VERSION ""

NS_ :

BS_:

BU_: EON PED IBST EPAS GAS_ACTUATOR BRAKE_ACTUATOR STEER_ACTUATOR XXX

CM_ "Ocelot retrofit hardware CAN definitions";
CM_ "Source: github.com/RetroPilot/opendbc branch c2";
CM_ "Used by PriusPilot for aftermarket actuator control on Prius Gen 2 (NHW20)";

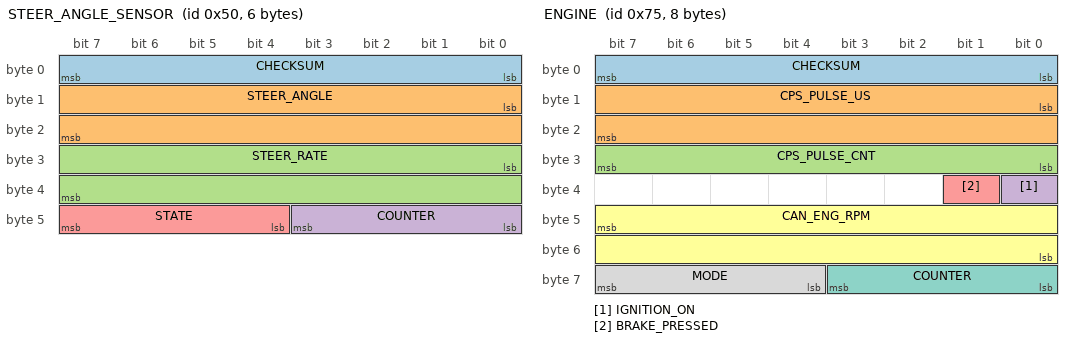
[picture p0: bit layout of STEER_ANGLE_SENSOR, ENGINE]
BO_ 80 STEER_ANGLE_SENSOR: 6 XXX
 SG_ CHECKSUM : 0|8@1+ (1,0) [0|255] "" XXX
 SG_ STEER_ANGLE : 8|16@1- (0.1,0) [0|65535] "" XXX
 SG_ STEER_RATE : 24|16@1+ (1,0) [0|65535] "" XXX
 SG_ COUNTER : 40|4@1+ (1,0) [0|15] "" XXX
 SG_ STATE : 44|4@1+ (1,0) [0|15] "" XXX

BO_ 117 ENGINE: 8 XXX
 SG_ CHECKSUM : 0|8@1+ (1,0) [0|255] "" XXX
 SG_ CPS_PULSE_US : 8|16@1+ (1,0) [0|65535] "" XXX
 SG_ CPS_PULSE_CNT : 24|8@1+ (1,0) [0|255] "" XXX
 SG_ IGNITION_ON : 32|1@0+ (1,0) [0|1] "" XXX
 SG_ BRAKE_PRESSED : 33|1@0+ (1,0) [0|1] "" XXX
 SG_ CAN_ENG_RPM : 47|16@0+ (1,0) [0|65535] "" XXX
 SG_ COUNTER : 56|4@1+ (1,0) [0|7] "" XXX
 SG_ MODE : 60|4@1+ (1,0) [0|15] "" XXX

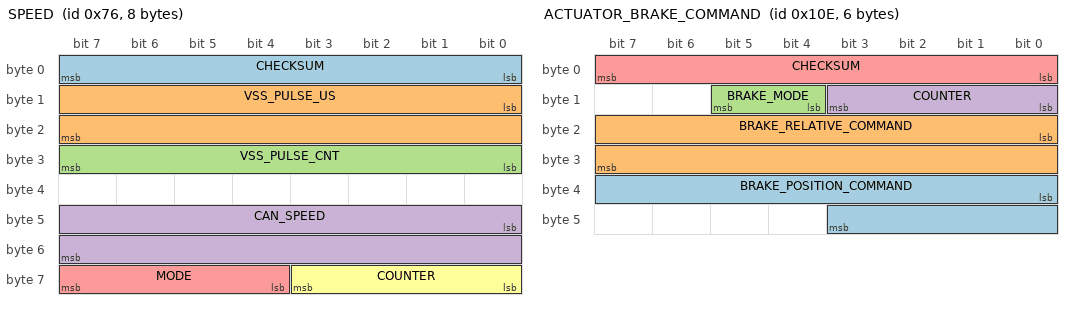
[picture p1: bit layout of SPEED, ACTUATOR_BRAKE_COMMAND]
BO_ 118 SPEED: 8 XXX
 SG_ CHECKSUM : 0|8@1+ (1,0) [0|255] "" XXX
 SG_ VSS_PULSE_US : 8|16@1+ (1,0) [0|65535] "" XXX
 SG_ VSS_PULSE_CNT : 24|8@1+ (1,0) [0|255] "" XXX
 SG_ CAN_SPEED : 40|16@1+ (1,0) [0|16777215] "" XXX
 SG_ MODE : 60|4@1+ (1,0) [0|15] "" XXX
 SG_ COUNTER : 56|4@1+ (1,0) [0|15] "" XXX

BO_ 256 CRUISE: 8 XXX
 SG_ CHECKSUM : 0|8@1+ (1,0) [0|255] "" XXX
 SG_ CANCEL : 16|1@1+ (1,0) [0|1] "" XXX
 SG_ SET_DOWN : 17|1@1+ (1,0) [0|1] "" XXX
 SG_ RES_UP : 18|1@1+ (1,0) [0|1] "" XXX
 SG_ ON_OFF : 19|1@1+ (1,0) [0|1] "" XXX
 SG_ ADC_1 : 31|16@1+ (1,0) [0|65535] "" XXX
 SG_ ADC_2 : 47|16@1+ (1,0) [0|65535] "" XXX
 SG_ COUNTER : 56|4@1+ (1,0) [0|15] "" XXX
 SG_ MODE : 60|4@1+ (1,0) [0|15] "" XXX

BO_ 270 ACTUATOR_BRAKE_COMMAND: 6 EON
 SG_ BRAKE_POSITION_COMMAND : 32|12@1+ (0.015625,-5) [-5|47] "mm" BRAKE_ACTUATOR
 SG_ BRAKE_RELATIVE_COMMAND : 16|16@1+ (0.0078125,-252) [-252|252] "" BRAKE_ACTUATOR
 SG_ BRAKE_MODE : 12|2@1+ (1,0) [0|3] "" BRAKE_ACTUATOR
 SG_ COUNTER : 8|4@1+ (1,0) [0|15] "" BRAKE_ACTUATOR
 SG_ CHECKSUM : 0|8@1+ (1,0) [0|255] "" BRAKE_ACTUATOR

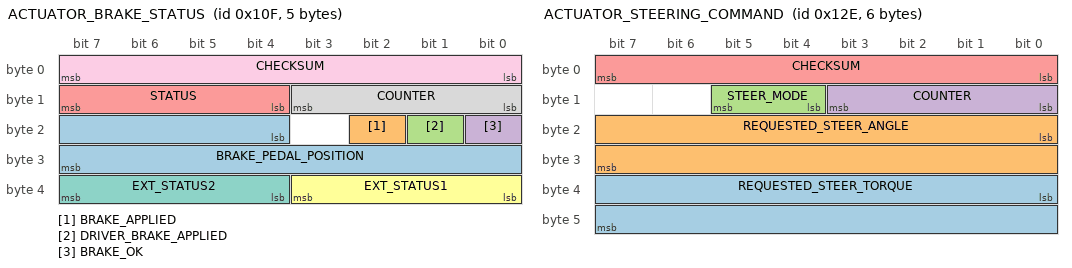
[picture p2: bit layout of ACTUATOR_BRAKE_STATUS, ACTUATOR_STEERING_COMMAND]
BO_ 271 ACTUATOR_BRAKE_STATUS: 5 BRAKE_ACTUATOR
 SG_ BRAKE_PEDAL_POSITION : 20|12@1+ (0.015625,-5) [-5|47] "mm" EON
 SG_ BRAKE_APPLIED : 18|1@1+ (1,0) [0|1] "" EON
 SG_ DRIVER_BRAKE_APPLIED : 17|1@1+ (1,0) [0|1] "" EON
 SG_ BRAKE_OK : 16|1@1+ (1,0) [0|1] "" EON
 SG_ STATUS : 12|4@1+ (1,0) [0|15] "" EON
 SG_ EXT_STATUS1 : 32|4@1+ (1,0) [0|15] "" EON
 SG_ EXT_STATUS2 : 36|4@1+ (1,0) [0|15] "" EON
 SG_ COUNTER : 8|4@1+ (1,0) [0|15] "" EON
 SG_ CHECKSUM : 0|8@1+ (1,0) [0|255] "" EON

BO_ 302 ACTUATOR_STEERING_COMMAND: 6 EON
 SG_ REQUESTED_STEER_TORQUE : 32|16@1- (0.5,0) [-512|511.5] "Nm" STEER_ACTUATOR
 SG_ REQUESTED_STEER_ANGLE : 16|16@1- (0.1,0) [-1638.4|1638.3] "deg" STEER_ACTUATOR
 SG_ STEER_MODE : 12|2@1+ (1,0) [0|3] "" STEER_ACTUATOR
 SG_ COUNTER : 8|4@1+ (1,0) [0|15] "" STEER_ACTUATOR
 SG_ CHECKSUM : 0|8@1+ (1,0) [0|255] "" STEER_ACTUATOR

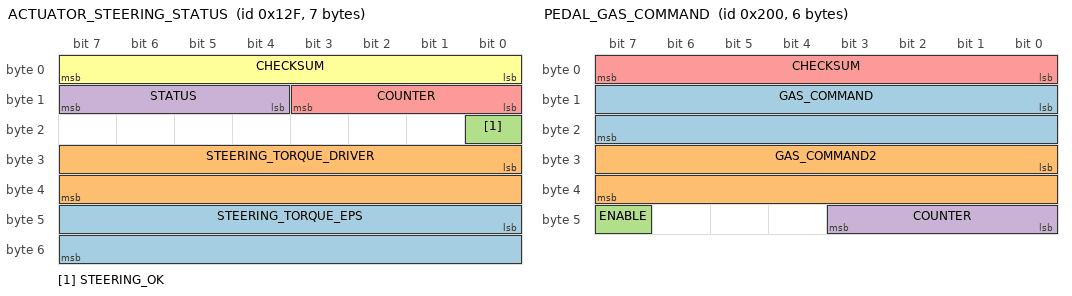
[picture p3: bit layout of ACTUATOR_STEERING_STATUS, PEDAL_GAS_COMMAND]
BO_ 303 ACTUATOR_STEERING_STATUS: 7 STEER_ACTUATOR
 SG_ STEERING_TORQUE_EPS : 40|16@1- (0.8,0) [-819.2|818.4] "Nm" EON
 SG_ STEERING_TORQUE_DRIVER : 24|16@1- (0.8,0) [-819.2|818.4] "Nm" EON
 SG_ STEERING_OK : 16|1@1+ (1,0) [0|1] "" EON
 SG_ STATUS : 12|4@1+ (1,0) [0|15] "" EON
 SG_ COUNTER : 8|4@1+ (1,0) [0|15] "" EON
 SG_ CHECKSUM : 0|8@1+ (1,0) [0|255] "" EON

BO_ 512 PEDAL_GAS_COMMAND: 6 EON
 SG_ GAS_COMMAND : 8|16@1+ (1,0) [0|1] "" PED
 SG_ GAS_COMMAND2 : 24|16@1+ (1,0) [0|1] "" PED
 SG_ ENABLE : 47|1@1+ (1,0) [0|1] "" PED
 SG_ COUNTER : 40|4@1+ (1,0) [0|15] "" PED
 SG_ CHECKSUM : 0|8@1+ (1,0) [0|255] "" PED

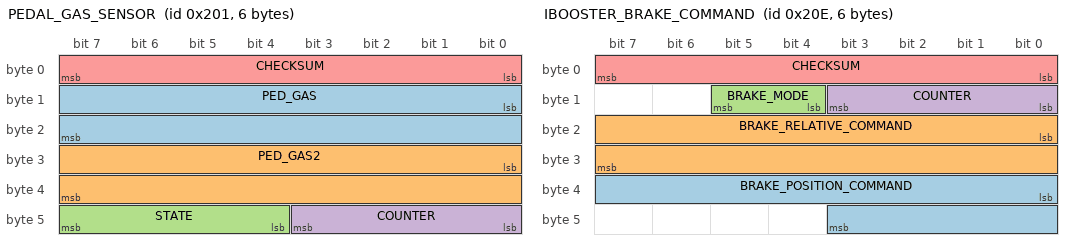
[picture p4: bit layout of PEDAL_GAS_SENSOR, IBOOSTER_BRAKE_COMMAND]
BO_ 513 PEDAL_GAS_SENSOR: 6 PED
 SG_ PED_GAS : 8|16@1+ (1,0) [0|1] "" EON
 SG_ PED_GAS2 : 24|16@1+ (1,0) [0|1] "" EON
 SG_ STATE : 44|4@1+ (1,0) [0|15] "" EON
 SG_ COUNTER : 40|4@1+ (1,0) [0|15] "" EON
 SG_ CHECKSUM : 0|8@1+ (1,0) [0|255] "" EON

BO_ 526 IBOOSTER_BRAKE_COMMAND: 6 EON
 SG_ BRAKE_POSITION_COMMAND : 32|12@1+ (0.015625,-5) [-5|47] "mm" IBST
 SG_ BRAKE_RELATIVE_COMMAND : 16|16@1+ (0.0078125,-252) [-252|252] "" IBST
 SG_ BRAKE_MODE : 12|2@1+ (1,0) [0|3] "" IBST
 SG_ COUNTER : 8|4@1+ (1,0) [0|15] "" IBST
 SG_ CHECKSUM : 0|8@1+ (1,0) [0|255] "" IBST

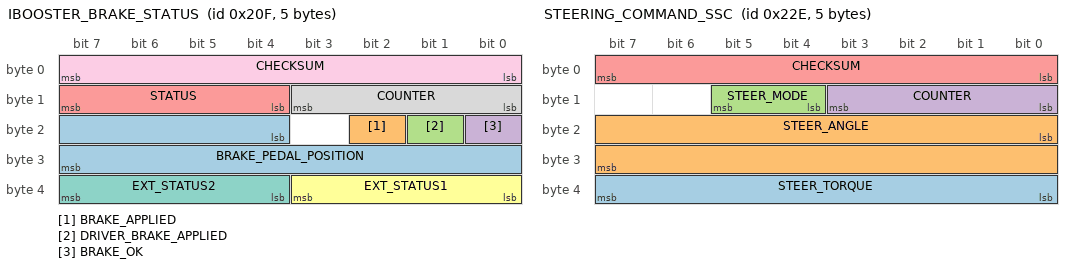
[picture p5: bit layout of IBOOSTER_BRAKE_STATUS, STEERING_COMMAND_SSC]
BO_ 527 IBOOSTER_BRAKE_STATUS: 5 IBST
 SG_ BRAKE_PEDAL_POSITION : 20|12@1+ (0.015625,-5) [-5|47] "mm" EON
 SG_ BRAKE_APPLIED : 18|1@1+ (1,0) [0|1] "" EON
 SG_ DRIVER_BRAKE_APPLIED : 17|1@1+ (1,0) [0|1] "" EON
 SG_ BRAKE_OK : 16|1@1+ (1,0) [0|1] "" EON
 SG_ STATUS : 12|4@1+ (1,0) [0|15] "" EON
 SG_ EXT_STATUS1 : 32|4@1+ (1,0) [0|15] "" EON
 SG_ EXT_STATUS2 : 36|4@1+ (1,0) [0|15] "" EON
 SG_ COUNTER : 8|4@1+ (1,0) [0|15] "" EON
 SG_ CHECKSUM : 0|8@1+ (1,0) [0|255] "" EON

BO_ 558 STEERING_COMMAND_SSC: 5 EON
 SG_ STEER_TORQUE : 32|8@1- (0.125,0) [-16|15.875] "Nm" EPAS
 SG_ STEER_ANGLE : 16|16@1- (0.125,0) [-4096|4095.875] "deg" EPAS
 SG_ STEER_MODE : 12|2@1+ (1,0) [0|3] "" EPAS
 SG_ COUNTER : 8|4@1+ (1,0) [0|15] "" EPAS
 SG_ CHECKSUM : 0|8@1+ (1,0) [0|255] "" EPAS

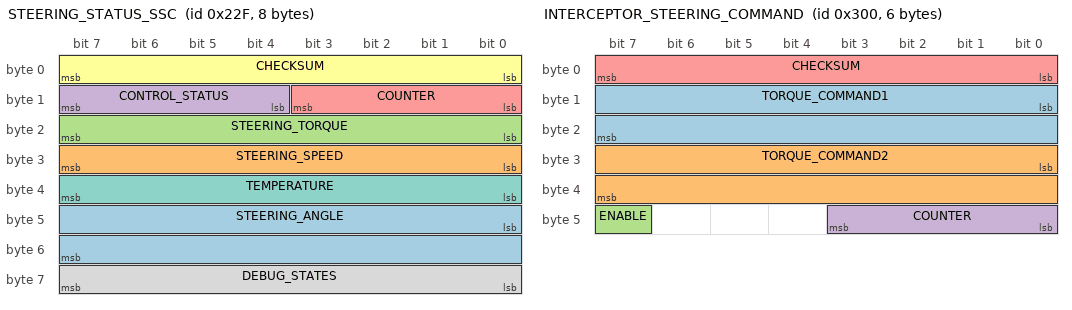
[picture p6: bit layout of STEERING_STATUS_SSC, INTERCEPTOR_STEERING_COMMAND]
BO_ 559 STEERING_STATUS_SSC: 8 EPAS
 SG_ STEERING_ANGLE : 40|16@1- (0.125,0) [-4096|4095.875] "deg" EON
 SG_ STEERING_SPEED : 24|8@1- (0.015625,0) [-2|1.984375] "rev/s" EON
 SG_ STEERING_TORQUE : 16|8@1- (0.125,0) [-16|15.875] "Nm" EON
 SG_ CONTROL_STATUS : 12|4@1+ (1,0) [0|15] "" EON
 SG_ COUNTER : 8|4@1+ (1,0) [0|15] "" EON
 SG_ CHECKSUM : 0|8@1+ (1,0) [0|255] "" EON
 SG_ TEMPERATURE : 32|8@1+ (1,-60) [-60|195] "C" EON
 SG_ DEBUG_STATES : 56|8@1+ (1,0) [0|255] "" EON

BO_ 768 INTERCEPTOR_STEERING_COMMAND: 6 EON
 SG_ TORQUE_COMMAND1 : 8|16@1- (1,0) [0|1] "" PED
 SG_ TORQUE_COMMAND2 : 24|16@1- (1,0) [0|1] "" PED
 SG_ ENABLE : 47|1@1+ (1,0) [0|1] "" PED
 SG_ COUNTER : 40|4@1+ (1,0) [0|15] "" PED
 SG_ CHECKSUM : 0|8@1+ (1,0) [0|255] "" PED

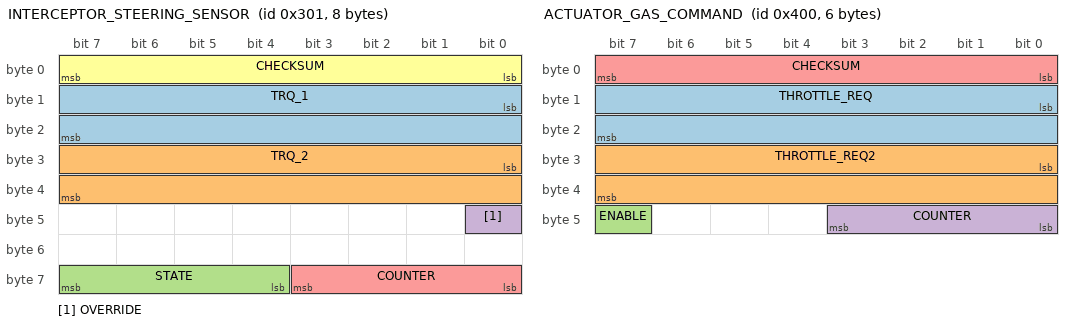
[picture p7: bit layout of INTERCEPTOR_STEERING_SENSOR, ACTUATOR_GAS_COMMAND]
BO_ 769 INTERCEPTOR_STEERING_SENSOR: 8 PED
 SG_ TRQ_1 : 8|16@1+ (0.275676,-33.3567) [0|1] "" EON
 SG_ TRQ_2 : 24|16@1+ (0.13629,-32.71) [0|1] "" EON
 SG_ STATE : 60|4@1+ (1,0) [0|15] "" EON
 SG_ OVERRIDE : 40|1@1+ (1,0) [0|1] "" EON
 SG_ COUNTER : 56|4@1+ (1,0) [0|15] "" EON
 SG_ CHECKSUM : 0|8@1+ (1,0) [0|255] "" EON

BO_ 1024 ACTUATOR_GAS_COMMAND: 6 EON
 SG_ THROTTLE_REQ : 8|16@1+ (1,0) [0|1] "" GAS_ACTUATOR
 SG_ THROTTLE_REQ2 : 24|16@1+ (1,0) [0|1] "" GAS_ACTUATOR
 SG_ ENABLE : 47|1@1+ (1,0) [0|1] "" GAS_ACTUATOR
 SG_ COUNTER : 40|4@1+ (1,0) [0|15] "" GAS_ACTUATOR
 SG_ CHECKSUM : 0|8@1+ (1,0) [0|255] "" GAS_ACTUATOR

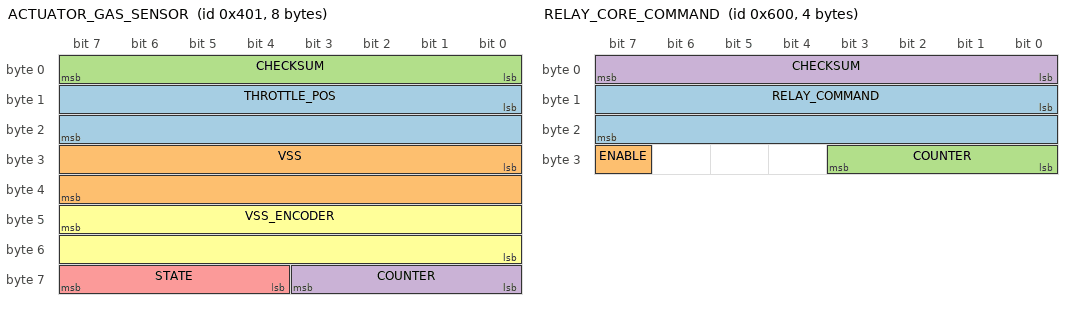
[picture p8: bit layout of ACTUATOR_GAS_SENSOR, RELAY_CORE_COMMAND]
BO_ 1025 ACTUATOR_GAS_SENSOR: 8 GAS_ACTUATOR
 SG_ THROTTLE_POS : 8|16@1+ (1,0) [0|1] "" EON
 SG_ VSS : 24|16@1+ (1,0) [0|1] "" EON
 SG_ CHECKSUM : 0|8@1+ (1,0) [0|255] "" EON
 SG_ COUNTER : 56|4@1+ (1,0) [0|15] "" EON
 SG_ STATE : 60|4@1+ (1,0) [0|15] "" EON
 SG_ VSS_ENCODER : 47|16@0+ (1,0) [0|65535] "" XXX

BO_ 1536 RELAY_CORE_COMMAND: 4 EON
 SG_ RELAY_COMMAND : 8|16@1+ (1,0) [0|1] "" PED
 SG_ ENABLE : 31|1@1+ (1,0) [0|1] "" PED
 SG_ COUNTER : 24|4@1+ (1,0) [0|15] "" PED
 SG_ CHECKSUM : 0|8@1+ (1,0) [0|255] "" PED

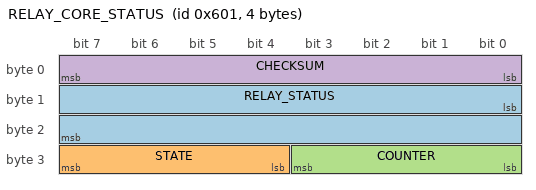
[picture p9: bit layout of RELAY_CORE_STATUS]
BO_ 1537 RELAY_CORE_STATUS: 4 PED
 SG_ RELAY_STATUS : 8|16@1+ (1,0) [0|1] "" EON
 SG_ STATE : 28|4@1+ (1,0) [0|15] "" EON
 SG_ COUNTER : 24|4@1+ (1,0) [0|15] "" EON
 SG_ CHECKSUM : 0|8@1+ (1,0) [0|255] "" EON

VAL_ 526 BRAKE_MODE 3 "Reserved" 2 "Position Control" 1 "Relative Control" 0 "Disengaged" ;
VAL_ 527 BRAKE_OK 1 "Yes" 0 "No" ;
VAL_ 527 STATUS 5 "FAULT_TIMEOUT" 4 "FAULT_STARTUP" 3 "FAULT_SCE" 2 "FAULT_SEND" 1 "FAULT_BAD_CHECKSUM" 0 "NO_FAULT" ;
